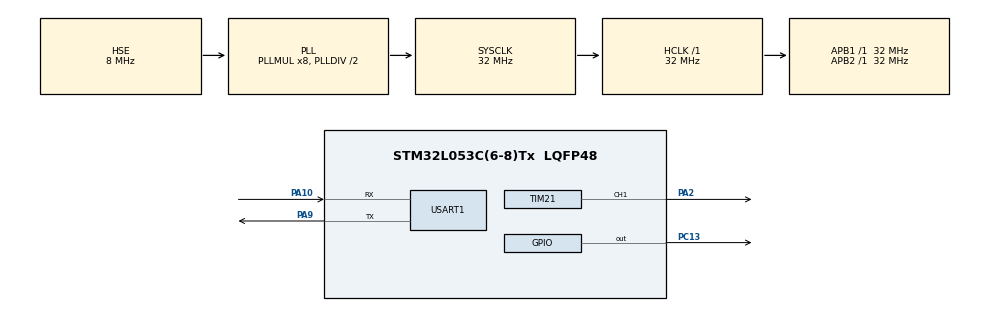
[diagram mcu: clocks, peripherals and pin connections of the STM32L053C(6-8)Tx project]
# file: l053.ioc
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Mcu.Family=STM32L0
Mcu.Name=STM32L053C(6-8)Tx
Mcu.Package=LQFP48
NVIC.RCC_CRS_IRQn=true\:0\:0\:true\:false\:true\:true\:false
NVIC.TIM21_IRQn=true\:0\:0\:true\:false\:true\:true\:true
NVIC.TIM6_DAC_IRQn=true\:0\:0\:false\:false\:true\:false\:true
NVIC.TimeBase=TIM6_DAC_IRQn
NVIC.TimeBaseIP=TIM6
PA10.Mode=Asynchronous
PA10.Signal=USART1_RX
PA13.Mode=Serial_Wire
PA13.Signal=SYS_SWDIO
PA14.Mode=Serial_Wire
PA14.Signal=SYS_SWCLK
PA2.Signal=S_TIM21_CH1
PA9.Mode=Asynchronous
PA9.Signal=USART1_TX
PC13.Signal=GPIO_Output
PH0-OSC_IN.Mode=HSE-External-Oscillator
PH0-OSC_IN.Signal=RCC_OSC_IN
PH1-OSC_OUT.Mode=HSE-External-Oscillator
PH1-OSC_OUT.Signal=RCC_OSC_OUT
ProjectManager.HeapSize=0x200
ProjectManager.StackSize=0x400
ProjectManager.TargetToolchain=EWARM V8.32
RCC.AHBFreq_Value=32000000
RCC.APB1Freq_Value=32000000
RCC.APB1TimFreq_Value=32000000
RCC.APB2Freq_Value=32000000
RCC.APB2TimFreq_Value=32000000
RCC.HCLKFreq_Value=32000000
RCC.HSE_VALUE=8000000
RCC.HSI16_VALUE=16000000
RCC.HSI48_VALUE=48000000
RCC.HSI_VALUE=16000000
RCC.LSE_VALUE=32768
RCC.MSI_VALUE=2097000
RCC.PLLMUL=RCC_PLLMUL_8
RCC.PLLSourceVirtual=RCC_PLLSOURCE_HSE
RCC.SYSCLKFreq_VALUE=32000000
RCC.SYSCLKSource=RCC_SYSCLKSOURCE_PLLCLK
RCC.VCOOutputFreq_Value=64000000
SH.S_TIM21_CH1.0=TIM21_CH1,PWM Generation1 CH1
TIM21.AutoReloadPreload=TIM_AUTORELOAD_PRELOAD_ENABLE
TIM21.Channel-PWM\ Generation1\ CH1=TIM_CHANNEL_1
TIM21.Period=32000
TIM21.Prescaler=0
TIM21.Pulse-PWM\ Generation1\ CH1=0
USART1.VirtualMode-Asynchronous=VM_ASYNC
VP_SYS_VS_tim6.Mode=TIM6
VP_TIM21_VS_ClockSourceINT.Mode=Internal
board=custom

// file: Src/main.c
/* USER CODE BEGIN Header */
/**
  ******************************************************************************
  * @file           : main.c
  * @brief          : Main program body
  ******************************************************************************
  * @attention
  *
  * <h2><center>&copy; Copyright (c) 2021 STMicroelectronics.
  * All rights reserved.</center></h2>
  *
  * This software component is licensed by ST under BSD 3-Clause license,
  * the "License"; You may not use this file except in compliance with the
  * License. You may obtain a copy of the License at:
  *                        opensource.org/licenses/BSD-3-Clause
  *
  ******************************************************************************
  */
/* USER CODE END Header */

#include "main.h"
#include "tim.h"
#include "usart.h"
#include "gpio.h"

/* USER CODE BEGIN Includes */
#include "timirq.h"
/* USER CODE END Includes */

void SystemClock_Config(void);

int main(void)
{

  /* MCU Configuration--------------------------------------------------------*/

  /* Reset of all peripherals, Initializes the Flash interface and the Systick. */
  HAL_Init();

  /* Configure the system clock */
  SystemClock_Config();

  /* Initialize all configured peripherals */
  MX_GPIO_Init();
  MX_USART1_UART_Init();
  MX_TIM21_Init();

  /* Infinite loop */
  /* USER CODE BEGIN WHILE */
  while (1)
  {
    readPrint();
    /* USER CODE END WHILE */

  }
}

void SystemClock_Config(void)
{
  RCC_OscInitTypeDef RCC_OscInitStruct = {0};
  RCC_ClkInitTypeDef RCC_ClkInitStruct = {0};
  RCC_PeriphCLKInitTypeDef PeriphClkInit = {0};

  /** Configure the main internal regulator output voltage
  */
  __HAL_PWR_VOLTAGESCALING_CONFIG(PWR_REGULATOR_VOLTAGE_SCALE1);
  /** Initializes the CPU, AHB and APB busses clocks
  */
  RCC_OscInitStruct.OscillatorType = RCC_OSCILLATORTYPE_HSE;
  RCC_OscInitStruct.HSEState = RCC_HSE_ON;
  RCC_OscInitStruct.PLL.PLLState = RCC_PLL_ON;
  RCC_OscInitStruct.PLL.PLLSource = RCC_PLLSOURCE_HSE;
  RCC_OscInitStruct.PLL.PLLMUL = RCC_PLLMUL_8;
  RCC_OscInitStruct.PLL.PLLDIV = RCC_PLLDIV_2;
  if (HAL_RCC_OscConfig(&RCC_OscInitStruct) != HAL_OK)
  {
    Error_Handler();
  }
  /** Initializes the CPU, AHB and APB busses clocks
  */
  RCC_ClkInitStruct.ClockType = RCC_CLOCKTYPE_HCLK|RCC_CLOCKTYPE_SYSCLK
                              |RCC_CLOCKTYPE_PCLK1|RCC_CLOCKTYPE_PCLK2;
  RCC_ClkInitStruct.SYSCLKSource = RCC_SYSCLKSOURCE_PLLCLK;
  RCC_ClkInitStruct.AHBCLKDivider = RCC_SYSCLK_DIV1;
  RCC_ClkInitStruct.APB1CLKDivider = RCC_HCLK_DIV1;
  RCC_ClkInitStruct.APB2CLKDivider = RCC_HCLK_DIV1;

  if (HAL_RCC_ClockConfig(&RCC_ClkInitStruct, FLASH_LATENCY_1) != HAL_OK)
  {
    Error_Handler();
  }
  PeriphClkInit.PeriphClockSelection = RCC_PERIPHCLK_USART1;
  PeriphClkInit.Usart1ClockSelection = RCC_USART1CLKSOURCE_PCLK2;
  if (HAL_RCCEx_PeriphCLKConfig(&PeriphClkInit) != HAL_OK)
  {
    Error_Handler();
  }
}

 /**
  * @brief  Period elapsed callback in non blocking mode
  * @note   This function is called  when TIM6 interrupt took place, inside
  * HAL_TIM_IRQHandler(). It makes a direct call to HAL_IncTick() to increment
  * a global variable "uwTick" used as application time base.
  * @param  htim : TIM handle
  * @retval None
  */
void HAL_TIM_PeriodElapsedCallback(TIM_HandleTypeDef *htim)
{
  if (htim->Instance == TIM6) {
    HAL_IncTick();
  }
  /* USER CODE BEGIN Callback 1 */
  if(htim->Instance == TIM21)
    TIM21IRQ();
  /* USER CODE END Callback 1 */
}

void Error_Handler(void)
{
}

/************************ (C) COPYRIGHT STMicroelectronics *****END OF FILE****/
